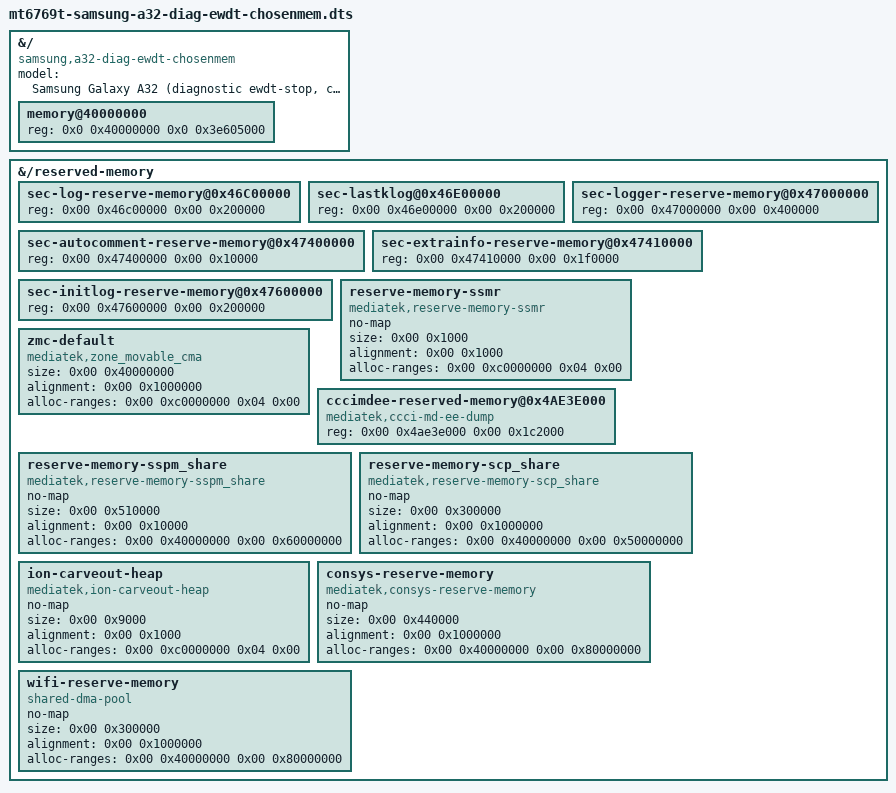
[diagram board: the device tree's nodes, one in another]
// SPDX-License-Identifier: GPL-2.0-only
/*
 * DT-ONLY graft B: chosen+mem (ewdt-stop lane).
 *
 * Mechanism: textual #include of the UNMODIFIED minimal DT
 * (mt6769t-samsung-a32-diag-minimal.dts, READ-ONLY) + deltas.
 * Kernel/ramdisk/cmdline/geometry pinned to the ewdt-stop lane
 * (Image-ewdt-stop.gz + Phase-7 ramdisk + 81 B cmdline).
 *
 * Deltas (ATOMIC memory+reserved-memory group kept together):
 *  1. memory@40000000 delete+replace with pmOS contract
 *     reg = <0x0 0x40000000 0x0 0x3e605000> (~998 MiB, top 0x7E605000).
 *  2. Graft the pmOS 14-node vendor reserved-memory set verbatim
 *     (regs/compats/no-map/size/alloc-ranges as in the pmOS DTB).
 *  3. Keep mainline ramoops@4d010000 + ram_console@4d000000 UNCHANGED.
 *     Overlap check (static-reg nodes only):
 *       ramoops 0x4D010000-0x4D0F0000; ram_console 0x4D000000-0x4D010000.
 *       sec-* fixed regions end at 0x47800000 (sec-initlog 0x47600000+0x200000).
 *       cccimdee fixed region 0x4AE3E000+0x1C2000 = 0x4B000000 (ends before 0x4D).
 *       All other pmOS nodes are dynamic (size+alloc-ranges, no static reg).
 *       No fb reserved region exists in pmOS (mtkfb@0 has no reg).
 *       => NO OVERLAP, ramoops KEPT. If overlap had existed it would have
 *       been dropped via /delete-node/ and documented here.
 *  4. chosen: NO DELTA. Mainline stdout-path (&uart0) + SoC bootargs
 *     "clk_ignore_unused" are kept as merged (SoC chosen + minimal
 *     stdout-path addition). No pmOS bootargs grafted (bootargs stay
 *     LK-safe; image cmdline is the pinned 81 B Phase-7 string).
 *  5. Distinct board identity (model/compatible).
 */

#include "mt6769t-samsung-a32-diag-minimal.dts"

/* B delta 1: pmOS RAM contract (delete + replace). */
&{/} {
	/delete-node/ memory@40000000;
	memory@40000000 {
		device_type = "memory";
		reg = <0x0 0x40000000 0x0 0x3e605000>; /* pmOS: ~998 MiB, top 0x7E605000 */
	};
};

/* B delta 2: pmOS 14-node vendor reserved-memory set (verbatim). */
&{/reserved-memory} {
	sec-log-reserve-memory@0x46C00000 {
		reg = <0x00 0x46c00000 0x00 0x200000>;
	};
	sec-lastklog@0x46E00000 {
		reg = <0x00 0x46e00000 0x00 0x200000>;
	};
	sec-logger-reserve-memory@0x47000000 {
		reg = <0x00 0x47000000 0x00 0x400000>;
	};
	sec-autocomment-reserve-memory@0x47400000 {
		reg = <0x00 0x47400000 0x00 0x10000>;
	};
	sec-extrainfo-reserve-memory@0x47410000 {
		reg = <0x00 0x47410000 0x00 0x1f0000>;
	};
	sec-initlog-reserve-memory@0x47600000 {
		reg = <0x00 0x47600000 0x00 0x200000>;
	};
	reserve-memory-ssmr {
		compatible = "mediatek,reserve-memory-ssmr";
		no-map;
		size = <0x00 0x1000>;
		alignment = <0x00 0x1000>;
		alloc-ranges = <0x00 0xc0000000 0x04 0x00>;
	};
	zmc-default {
		compatible = "mediatek,zone_movable_cma";
		size = <0x00 0x40000000>;
		alignment = <0x00 0x1000000>;
		alloc-ranges = <0x00 0xc0000000 0x04 0x00>;
	};
	cccimdee-reserved-memory@0x4AE3E000 {
		compatible = "mediatek,ccci-md-ee-dump";
		reg = <0x00 0x4ae3e000 0x00 0x1c2000>;
	};
	reserve-memory-sspm_share {
		compatible = "mediatek,reserve-memory-sspm_share";
		no-map;
		status = "okay";
		size = <0x00 0x510000>;
		alignment = <0x00 0x10000>;
		alloc-ranges = <0x00 0x40000000 0x00 0x60000000>;
	};
	reserve-memory-scp_share {
		compatible = "mediatek,reserve-memory-scp_share";
		no-map;
		size = <0x00 0x300000>;
		alignment = <0x00 0x1000000>;
		alloc-ranges = <0x00 0x40000000 0x00 0x50000000>;
	};
	ion-carveout-heap {
		compatible = "mediatek,ion-carveout-heap";
		no-map;
		size = <0x00 0x9000>;
		alignment = <0x00 0x1000>;
		alloc-ranges = <0x00 0xc0000000 0x04 0x00>;
	};
	consys-reserve-memory {
		compatible = "mediatek,consys-reserve-memory";
		no-map;
		size = <0x00 0x440000>;
		alignment = <0x00 0x1000000>;
		alloc-ranges = <0x00 0x40000000 0x00 0x80000000>;
	};
	wifi-reserve-memory {
		compatible = "shared-dma-pool";
		no-map;
		size = <0x00 0x300000>;
		alignment = <0x00 0x1000000>;
		alloc-ranges = <0x00 0x40000000 0x00 0x80000000>;
	};
};

/* B delta 3: distinct board identity. */
&{/} {
	model = "Samsung Galaxy A32 (diagnostic ewdt-stop, chosen+mem)";
	compatible = "samsung,a32-diag-ewdt-chosenmem", "mediatek,mt6769t", "mediatek,mt6768";
};
